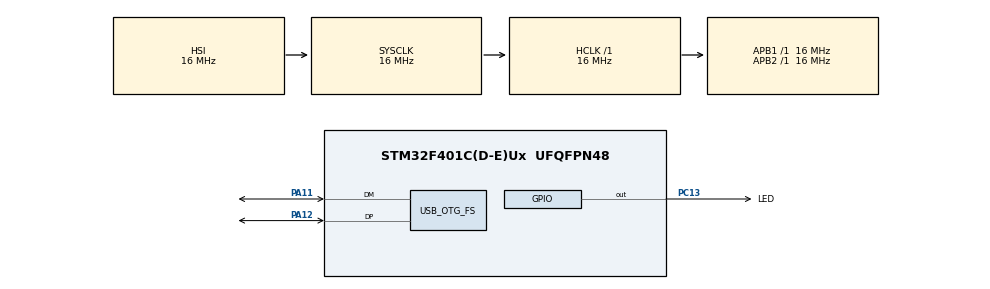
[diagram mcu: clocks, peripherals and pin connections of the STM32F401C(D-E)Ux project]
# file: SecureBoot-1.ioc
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Mcu.Family=STM32F4
Mcu.Name=STM32F401C(D-E)Ux
Mcu.Package=UFQFPN48
NVIC.OTG_FS_IRQn=true\:0\:0\:false\:false\:true\:true\:true\:true
NVIC.PriorityGroup=NVIC_PRIORITYGROUP_4
PA11.Mode=Device_Only
PA11.Signal=USB_OTG_FS_DM
PA12.Mode=Device_Only
PA12.Signal=USB_OTG_FS_DP
PA13.Mode=Serial_Wire
PA13.Signal=SYS_JTMS-SWDIO
PA14.Mode=Serial_Wire
PA14.Signal=SYS_JTCK-SWCLK
PC13-ANTI_TAMP.GPIO_Label=LED
PC13-ANTI_TAMP.Signal=GPIO_Output
PC14-OSC32_IN.Mode=LSE-External-Oscillator
PC14-OSC32_IN.Signal=RCC_OSC32_IN
PC15-OSC32_OUT.Mode=LSE-External-Oscillator
PC15-OSC32_OUT.Signal=RCC_OSC32_OUT
PH0\ -\ OSC_IN.Mode=HSE-External-Oscillator
PH0\ -\ OSC_IN.Signal=RCC_OSC_IN
PH1\ -\ OSC_OUT.Mode=HSE-External-Oscillator
PH1\ -\ OSC_OUT.Signal=RCC_OSC_OUT
ProjectManager.HeapSize=0x200
ProjectManager.StackSize=0x400
ProjectManager.TargetToolchain=STM32CubeIDE
RCC.48MHZClocksFreq_Value=48000000
RCC.AHBFreq_Value=16000000
RCC.APB1Freq_Value=16000000
RCC.APB1TimFreq_Value=16000000
RCC.APB2Freq_Value=16000000
RCC.APB2TimFreq_Value=16000000
RCC.CortexFreq_Value=16000000
RCC.HCLKFreq_Value=16000000
RCC.HSE_VALUE=25000000
RCC.HSI_VALUE=16000000
RCC.PLLM=25
RCC.SYSCLKFreq_VALUE=16000000
RCC.VCOOutputFreq_Value=192000000
USB_OTG_FS.VirtualMode=Device_Only
VP_CRC_VS_CRC.Mode=CRC_Activate
board=custom

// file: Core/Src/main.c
/* USER CODE BEGIN Header */
/**
  ******************************************************************************
  * @file           : main.c
  * @brief          : Main program body
  ******************************************************************************
  * @attention
  *
  * Copyright (c) 2025 STMicroelectronics.
  * All rights reserved.
  *
  * This software is licensed under terms that can be found in the LICENSE file
  * in the root directory of this software component.
  * If no LICENSE file comes with this software, it is provided AS-IS.
  *
  ******************************************************************************
  */
/* USER CODE END Header */
#include "main.h"

/* USER CODE BEGIN Includes */

#include "boot.h"
#include "tusb.h"

/* USER CODE END Includes */

CRC_HandleTypeDef hcrc;

PCD_HandleTypeDef hpcd_USB_OTG_FS;

void SystemClock_Config(void);
static void MX_GPIO_Init(void);
static void MX_CRC_Init(void);
static void MX_USB_OTG_FS_PCD_Init(void);

/* USER CODE BEGIN 0 */

int _write(int file, char *ptr, int len)
{
    // Wait until the USB CDC is ready
    while (CDC_Transmit_FS((uint8_t*)ptr, len) == USBD_BUSY) {}

    return len;
}

#define WORDS_TO_PRINT 10

void print_memory(const char* label, uint8_t* addr) {
    printf("%s @ %p: ", label, addr);
    for (int i = 0; i < WORDS_TO_PRINT; i++) {
        uint32_t word = *(uint32_t*)(addr + i*4);  // 4 bytes per word
        printf("0x%08lX ", word);
    }
    printf("\r\n");
}

/* USER CODE END 0 */

int main(void)
{

  /* MCU Configuration--------------------------------------------------------*/

  /* Reset of all peripherals, Initializes the Flash interface and the Systick. */
  HAL_Init();

  /* USER CODE BEGIN Init */

  tusb_init();

  /* USER CODE END Init */

  /* Configure the system clock */
  SystemClock_Config();

  /* Initialize all configured peripherals */
  MX_GPIO_Init();
  MX_CRC_Init();
  MX_USB_OTG_FS_PCD_Init();
  /* USER CODE BEGIN 2 */

  HAL_Delay(3000);

  printf("Bootloader loaded!\r\n");

  //boot();

  /* USER CODE END 2 */

  /* Infinite loop */
  /* USER CODE BEGIN WHILE */
  while (1)
  {
	  //HAL_GPIO_TogglePin(LED_GPIO_Port, LED_Pin);
	  //HAL_Delay(1000);
	  tud_task();
    /* USER CODE END WHILE */

  }
}

void SystemClock_Config(void)
{
  RCC_OscInitTypeDef RCC_OscInitStruct = {0};
  RCC_ClkInitTypeDef RCC_ClkInitStruct = {0};

  /** Configure the main internal regulator output voltage
  */
  __HAL_RCC_PWR_CLK_ENABLE();
  __HAL_PWR_VOLTAGESCALING_CONFIG(PWR_REGULATOR_VOLTAGE_SCALE2);

  /** Initializes the RCC Oscillators according to the specified parameters
  * in the RCC_OscInitTypeDef structure.
  */
  RCC_OscInitStruct.OscillatorType = RCC_OSCILLATORTYPE_HSI|RCC_OSCILLATORTYPE_HSE;
  RCC_OscInitStruct.HSEState = RCC_HSE_ON;
  RCC_OscInitStruct.HSIState = RCC_HSI_ON;
  RCC_OscInitStruct.HSICalibrationValue = RCC_HSICALIBRATION_DEFAULT;
  RCC_OscInitStruct.PLL.PLLState = RCC_PLL_ON;
  RCC_OscInitStruct.PLL.PLLSource = RCC_PLLSOURCE_HSE;
  RCC_OscInitStruct.PLL.PLLM = 25;
  RCC_OscInitStruct.PLL.PLLN = 192;
  RCC_OscInitStruct.PLL.PLLP = RCC_PLLP_DIV2;
  RCC_OscInitStruct.PLL.PLLQ = 4;
  if (HAL_RCC_OscConfig(&RCC_OscInitStruct) != HAL_OK)
  {
    Error_Handler();
  }

  /** Initializes the CPU, AHB and APB buses clocks
  */
  RCC_ClkInitStruct.ClockType = RCC_CLOCKTYPE_HCLK|RCC_CLOCKTYPE_SYSCLK
                              |RCC_CLOCKTYPE_PCLK1|RCC_CLOCKTYPE_PCLK2;
  RCC_ClkInitStruct.SYSCLKSource = RCC_SYSCLKSOURCE_HSI;
  RCC_ClkInitStruct.AHBCLKDivider = RCC_SYSCLK_DIV1;
  RCC_ClkInitStruct.APB1CLKDivider = RCC_HCLK_DIV1;
  RCC_ClkInitStruct.APB2CLKDivider = RCC_HCLK_DIV1;

  if (HAL_RCC_ClockConfig(&RCC_ClkInitStruct, FLASH_LATENCY_0) != HAL_OK)
  {
    Error_Handler();
  }
}

static void MX_CRC_Init(void)
{

  hcrc.Instance = CRC;
  if (HAL_CRC_Init(&hcrc) != HAL_OK)
  {
    Error_Handler();
  }

}

static void MX_USB_OTG_FS_PCD_Init(void)
{

  hpcd_USB_OTG_FS.Instance = USB_OTG_FS;
  hpcd_USB_OTG_FS.Init.dev_endpoints = 4;
  hpcd_USB_OTG_FS.Init.speed = PCD_SPEED_FULL;
  hpcd_USB_OTG_FS.Init.dma_enable = DISABLE;
  hpcd_USB_OTG_FS.Init.phy_itface = PCD_PHY_EMBEDDED;
  hpcd_USB_OTG_FS.Init.Sof_enable = DISABLE;
  hpcd_USB_OTG_FS.Init.low_power_enable = DISABLE;
  hpcd_USB_OTG_FS.Init.lpm_enable = DISABLE;
  hpcd_USB_OTG_FS.Init.vbus_sensing_enable = DISABLE;
  hpcd_USB_OTG_FS.Init.use_dedicated_ep1 = DISABLE;
  if (HAL_PCD_Init(&hpcd_USB_OTG_FS) != HAL_OK)
  {
    Error_Handler();
  }

}

static void MX_GPIO_Init(void)
{
  GPIO_InitTypeDef GPIO_InitStruct = {0};

  /* GPIO Ports Clock Enable */
  __HAL_RCC_GPIOC_CLK_ENABLE();
  __HAL_RCC_GPIOH_CLK_ENABLE();
  __HAL_RCC_GPIOA_CLK_ENABLE();

  /*Configure GPIO pin Output Level */
  HAL_GPIO_WritePin(LED_GPIO_Port, LED_Pin, GPIO_PIN_RESET);

  /*Configure GPIO pin : LED_Pin */
  GPIO_InitStruct.Pin = LED_Pin;
  GPIO_InitStruct.Mode = GPIO_MODE_OUTPUT_PP;
  GPIO_InitStruct.Pull = GPIO_NOPULL;
  GPIO_InitStruct.Speed = GPIO_SPEED_FREQ_LOW;
  HAL_GPIO_Init(LED_GPIO_Port, &GPIO_InitStruct);

}

void Error_Handler(void)
{
  __disable_irq();
  while (1)
  {
  }
}
